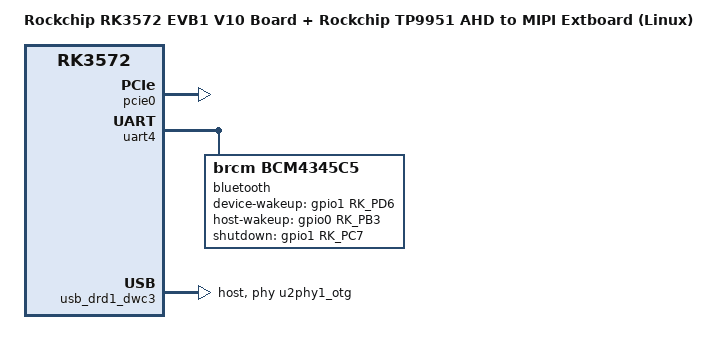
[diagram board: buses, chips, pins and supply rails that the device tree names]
// SPDX-License-Identifier: (GPL-2.0+ OR MIT)
/*
 * Copyright (c) 2026 Rockchip Electronics Co., Ltd.
 */

/dts-v1/;

#include "rk3572-evb1-v10.dtsi"
#include "rk3572-linux.dtsi"
#include "rk3572-tp9951-ahd-extboard.dtsi"

/ {
	model = "Rockchip RK3572 EVB1 V10 Board + Rockchip TP9951 AHD to MIPI Extboard (Linux)";
	compatible = "rockchip,rk3572-evb1-v10", "rockchip,rk3572";
};

&pcie0 {
	status = "okay";
};

&uart4 {
	status = "okay";
	pinctrl-names = "default";
	pinctrl-0 = <&uart4m1_xfer_pins &uart4m1_ctsn_pins &uart4m1_rtsn_pins>;
	uart-has-rtscts;

	bluetooth {
		compatible = "brcm,bcm4345c5";

		device-wakeup-gpios = <&gpio1 RK_PD6 GPIO_ACTIVE_HIGH>;
		host-wakeup-gpios = <&gpio0 RK_PB3 GPIO_ACTIVE_HIGH>;
		shutdown-gpios = <&gpio1 RK_PC7 GPIO_ACTIVE_HIGH>;
		max-speed = <1500000>;
	};
};

&usb_drd1_dwc3 {
	dr_mode = "host";
	maximum-speed = "high-speed";
	phys = <&u2phy1_otg>;
	phy-names = "usb2-phy";
	snps,dis_u2_susphy_quirk;
	snps,usb2-lpm-disable;
	status = "okay";
};

/delete-node/ &wireless_bluetooth;
